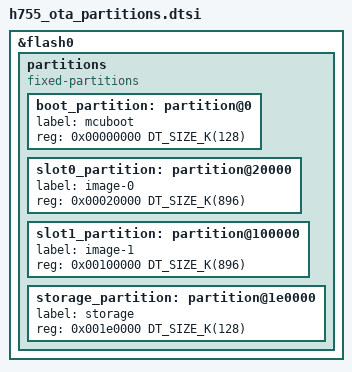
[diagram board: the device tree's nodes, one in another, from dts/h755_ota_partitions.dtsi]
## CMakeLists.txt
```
cmake_minimum_required(VERSION 3.20.0)

find_package(Zephyr REQUIRED HINTS $ENV{ZEPHYR_BASE})
project(ota_device)

target_sources(app PRIVATE src/main.c)
```

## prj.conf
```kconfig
CONFIG_GPIO=y
CONFIG_LOG=y
CONFIG_LOG_DEFAULT_LEVEL=3
CONFIG_MAIN_STACK_SIZE=2048
```

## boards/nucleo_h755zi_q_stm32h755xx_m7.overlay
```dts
#include "../dts/h755_ota_partitions.dtsi"

/ {
	chosen {
		zephyr,code-partition = &slot0_partition;
	};
};
```

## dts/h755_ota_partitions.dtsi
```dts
&flash0 {
	partitions {
		compatible = "fixed-partitions";
		#address-cells = <1>;
		#size-cells = <1>;

		boot_partition: partition@0 {
			label = "mcuboot";
			reg = <0x00000000 DT_SIZE_K(128)>;
		};

		slot0_partition: partition@20000 {
			label = "image-0";
			reg = <0x00020000 DT_SIZE_K(896)>;
		};

		slot1_partition: partition@100000 {
			label = "image-1";
			reg = <0x00100000 DT_SIZE_K(896)>;
		};

		storage_partition: partition@1e0000 {
			label = "storage";
			reg = <0x001e0000 DT_SIZE_K(128)>;
		};
	};
};
```

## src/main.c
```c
#include <zephyr/device.h>
#include <zephyr/drivers/gpio.h>
#include <zephyr/kernel.h>
#include <zephyr/logging/log.h>

LOG_MODULE_REGISTER(ota_device, LOG_LEVEL_INF);

static const struct gpio_dt_spec heartbeat_led = GPIO_DT_SPEC_GET(DT_ALIAS(led0), gpios);

int main(void)
{
	int result;

	if (!gpio_is_ready_dt(&heartbeat_led)) {
		LOG_ERR("Heartbeat LED controller is not ready");
		return 0;
	}

	result = gpio_pin_configure_dt(&heartbeat_led, GPIO_OUTPUT_INACTIVE);
	if (result != 0) {
		LOG_ERR("Heartbeat LED configuration failed: %d", result);
		return 0;
	}

	LOG_INF("STM32H755 OTA device bring-up started on %s", CONFIG_BOARD_TARGET);

	while (true) {
		result = gpio_pin_toggle_dt(&heartbeat_led);
		if (result != 0) {
			LOG_ERR("Heartbeat LED update failed: %d", result);
			return 0;
		}

		k_sleep(K_MSEC(500));
	}

	return 0;
}
```
